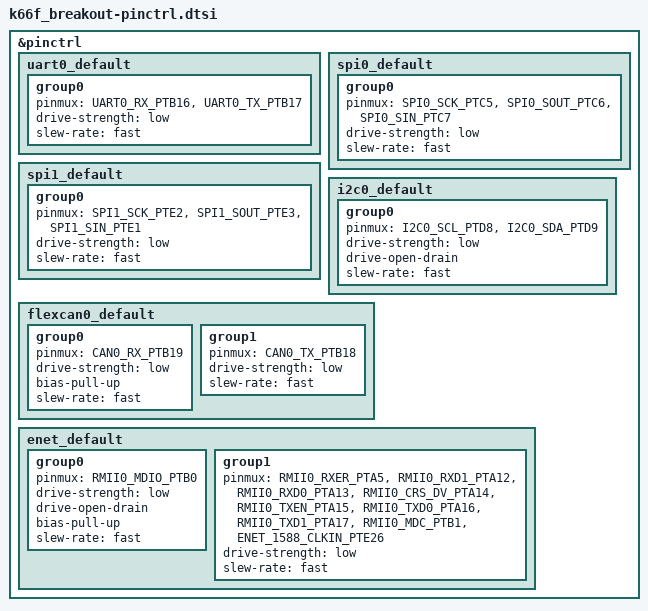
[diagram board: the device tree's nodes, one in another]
#include <nxp/kinetis/MK66FN2M0VMD18-pinctrl.h>

&pinctrl {
    uart0_default: uart0_default {
        group0 {
            pinmux = <UART0_RX_PTB16>,
                     <UART0_TX_PTB17>;
            drive-strength = "low";
            slew-rate = "fast";
        };
    };

    spi0_default: spi0_default {
        group0 {
            pinmux = <SPI0_SCK_PTC5>,
                     <SPI0_SOUT_PTC6>,
                     <SPI0_SIN_PTC7>;
            drive-strength = "low";
            slew-rate = "fast";
        };
    };

    spi1_default: spi1_default {
        group0 {
            pinmux = <SPI1_SCK_PTE2>,
                     <SPI1_SOUT_PTE3>,
                     <SPI1_SIN_PTE1>;
            drive-strength = "low";
            slew-rate = "fast";
        };
    };

    i2c0_default: i2c0_default {
        group0 {
            pinmux = <I2C0_SCL_PTD8>,
                     <I2C0_SDA_PTD9>;
            drive-strength = "low";
            drive-open-drain;
            slew-rate = "fast";
        };
    };

    flexcan0_default: flexcan0_default {
        group0 {
            pinmux = <CAN0_RX_PTB19>;
            drive-strength = "low";
            bias-pull-up;
            slew-rate = "fast";
        };
        group1 {
            pinmux = <CAN0_TX_PTB18>;
            drive-strength = "low";
            slew-rate = "fast";
        };
    };

    enet_default: enet_default {
        group0 {
            pinmux = <RMII0_MDIO_PTB0>;
            drive-strength = "low";
            drive-open-drain;
            bias-pull-up;
            slew-rate = "fast";
        };
        group1 {
            pinmux = <RMII0_RXER_PTA5>,
                     <RMII0_RXD1_PTA12>,
                     <RMII0_RXD0_PTA13>,
                     <RMII0_CRS_DV_PTA14>,
                     <RMII0_TXEN_PTA15>,
                     <RMII0_TXD0_PTA16>,
                     <RMII0_TXD1_PTA17>,
                     <RMII0_MDC_PTB1>,
                     <ENET_1588_CLKIN_PTE26>;
            drive-strength = "low";
            slew-rate = "fast";
        };
    };
};
